# AST1060 register map
File version: 1.0
CPU: CM4 r0p1, little endian, MPU, FPU, 4 interrupt priority bits, 256 interrupts
Registers are 32-bit, read-write, reset 0x0 unless marked. A register's access mark holds for its fields unless they carry their own. Offsets are from the block's base; [hi:lo] are bit positions; {n}, {i} and the like mark numbered series.

## i2cbuff
Base 0x7E7B0C00
Same registers: i2cbuff{n} {0x7E7B0C00+0x20*n} (n=1..13)
{0x0+4i} BUFF[{i}] (i=0..7) — I2C Buffer Mode Buff
  [31:0] Data

## i2cfilter
Base 0x7E7B2000
0x08 I2CFILTER008 — I2CFLT\_IRQEN
  [15:0] TOPIRQEN
0x0C I2CFILTER00C — I2CFLT\_IRQSTA
  [15:0] TOPIRQSTA ro

## i2c_filter_thr
Base 0x7E7B2200
Same registers: i2c_filter_thr1 0x7E7B2300, i2c_filter_thr2 0x7E7B2400, i2c_filter_thr3 0x7E7B2500
0x04 I2CFILTERTHR04 — I2CFLT\_THRN\_EN
  [0] EN
0x08 I2CFILTERTHR08 — I2CFLT\_THRN\_ADR
  [31:0] ADDR
0x0C I2CFILTERTHR0C — I2CFLT\_THRN\_CFG
  [31:0] CFG
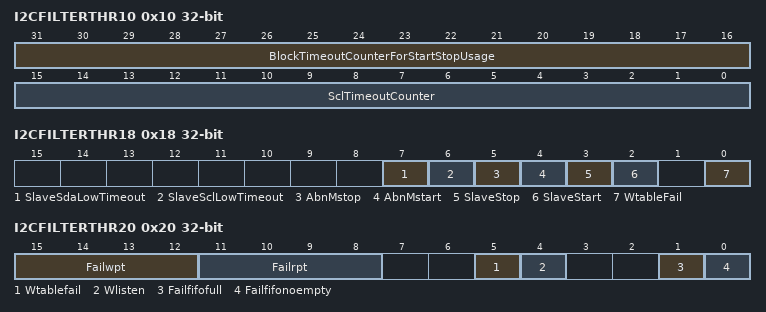
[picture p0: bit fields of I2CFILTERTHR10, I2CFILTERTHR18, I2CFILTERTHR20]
0x10 I2CFILTERTHR10 — I2CFLT\_THRN\_TMR
  [31:16] BlockTimeoutCounterForStartStopUsage, [15:0] SclTimeoutCounter
0x14 I2CFILTERTHR14 — I2CFLT\_THRN\_INTEN
  [7:0] INTEN
0x18 I2CFILTERTHR18 — I2CFLT\_THRN\_INTS
  [7] SlaveSdaLowTimeout
  [6] SlaveSclLowTimeout
  [5] AbnMstop — abnormal mstop
  [4] AbnMstart — abnormal mstart
  [3] SlaveStop
  [2] SlaveStart
  [0] WtableFail
0x20 I2CFILTERTHR20 — I2CFLT\_THRN\_STATUS
  [15:12] Failwpt, [11:8] Failrpt, [5] Wtablefail, [4] Wlisten, [1] Failfifofull, [0] Failfifonoempty
0x24 I2CFILTERTHR24 — I2CFLT\_THRN\_SEQ
  [31:0] RXSEQVAL ro
0x40 I2CFILTERTHR40 — I2CFLT\_THRN\_MAP0
  [31:0] MAP0
0x44 I2CFILTERTHR44 — I2CFLT\_THRN\_MAP1
  [31:0] MAP1
0x48 I2CFILTERTHR48 — I2CFLT\_THRN\_MAP2
  [31:0] MAP2
0x4C I2CFILTERTHR4C — I2CFLT\_THRN\_MAP3
  [31:0] MAP3
0x60 I2CFILTERTHR60 — I2CFLT\_THRN\_INFO
  [31:0] INFO ro

## spipf
Base 0x7E791000
Same registers: spipf1 0x7E792000, spipf2 0x7E793000, spipf3 0x7E794000
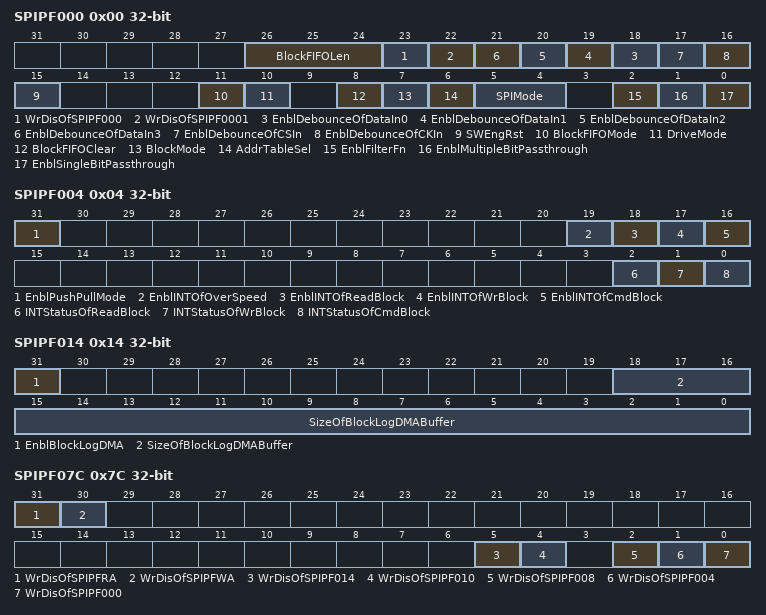
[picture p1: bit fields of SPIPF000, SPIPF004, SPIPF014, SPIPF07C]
0x00 SPIPF000 — Engine Control Register
  [26:24] BlockFIFOLen — Block FIFO length
  [23] WrDisOfSPIPF000 — Write Disable of hlinkSPIPF000
  [22] WrDisOfSPIPF0001 — Write Disable of hlinkSPIPF000
  [n+18] EnblDebounceOfDataIn{n} (n=0..3) — Enable Debounce of DataIn[{n}]
  [17] EnblDebounceOfCSIn — Enable Debounce of CSIn
  [16] EnblDebounceOfCKIn — Enable Debounce of CKIn
  [15] SWEngRst — SW Engine Reset
  [11] BlockFIFOMode
  [10] DriveMode
  [8] BlockFIFOClear
  [7] BlockMode
  [6] AddrTableSel — Address Table Selection
  [5:4] SPIMode
  [2] EnblFilterFn — Enable Filter function
  [1] EnblMultipleBitPassthrough — Enable Multiple Bit Passthrough
  [0] EnblSingleBitPassthrough — Enable Single Bit Passthrough
0x04 SPIPF004 — Interrupt Enable and Status Register
  [31] EnblPushPullMode — Enable push pull mode
  [19] EnblINTOfOverSpeed — Enable Interrupt of Over Speed
  [18] EnblINTOfReadBlock — Enable Interrupt of Read Block
  [17] EnblINTOfWrBlock — Enable Interrupt of Write Block
  [16] EnblINTOfCmdBlock — Enable Interrupt of Command Block
  [2] INTStatusOfReadBlock — Interrupt Status of Read Block
  [1] INTStatusOfWrBlock — Interrupt Status of Write Block
  [0] INTStatusOfCmdBlock — Interrupt Status of Command Block
0x08 SPIPF008 — EAR and Over Speed Register
  [7:0] CurExtendAddrRegRxdFromSPIMaster ro — Current Extend Address Register Received from SPI master
0x0C SPIPF00C — Block FIFO Data Register
  [31:0] ReadDataOfBlockFIFO ro
0x10 SPIPF010 — Block Log DMA Base Address
  [31:2] BlockLogDMABaseAddr
0x14 SPIPF014 — Block Log DMA Size
  [31] EnblBlockLogDMA — Enable Block Log DMA
  [18:0] SizeOfBlockLogDMABuffer
0x18 SPIPF018 — Block Log DMA Write Pointer
  [17:0] BlockLogDMAWrPointer ro
0x7C SPIPF07C — Write Disable Register
  [31] WrDisOfSPIPFRA — Write Disable of hlinkSPIPFRA
  [30] WrDisOfSPIPFWA — Write Disable of hlinkSPIPFWA
  [5] WrDisOfSPIPF014 — Write Disable of hlinkSPIPF014
  [4] WrDisOfSPIPF010 — Write Disable of hlinkSPIPF010
  [2] WrDisOfSPIPF008 — Write Disable of hlinkSPIPF008
  [1] WrDisOfSPIPF004 — Write Disable of hlinkSPIPF004
  [0] WrDisOfSPIPF000 — Write Disable of hlinkSPIPF000
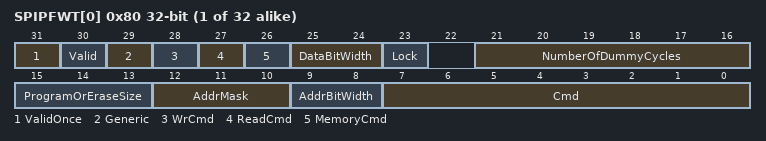
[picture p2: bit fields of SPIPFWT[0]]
{0x80+4i} SPIPFWT[{i}] (i=0..31) — Allow Command Table \#1 $\sim$ \#32
  [31] ValidOnce
  [30] Valid
  [29] Generic
  [28] WrCmd — Write Command
  [27] ReadCmd — Read Command
  [26] MemoryCmd — Memory Command
  [25:24] DataBitWidth
  [23] Lock
  [21:16] NumberOfDummyCycles
  [15:13] ProgramOrEraseSize
  [12:10] AddrMask — Address Mask
  [9:8] AddrBitWidth — Address Bit width
  [7:0] Cmd — Command
{0x100+4i} SPIPFWA[{i}] (i=0..511) — Write Address Table (\hlink{SPIPF000

## timer
Base 0x7E782000
Same registers: timer1 0x7E782010, timer2 0x7E782020, timer3 0x7E782040, timer4 0x7E782050, timer5 0x7E782060, timer6 0x7E782070, timer7 0x7E782080
0x00 TIMER000 — Counter \#1 Status Register
  [31:0] CounterSts — Counter status
0x04 TIMER004 — Counter \#1 Reload Value Register
  [31:0] CounterReloadValueReg — Counter reload value register
0x08 TIMER008 — Counter \#1 First Matching Register
  [31:0] FirstSetMatchReg — First set match register
0x0C TIMER00C — Counter \#1 Second Matching Register
  [31:0] SecondaryMatchReg — Secondary match register

## timerg
Base 0x7E782000
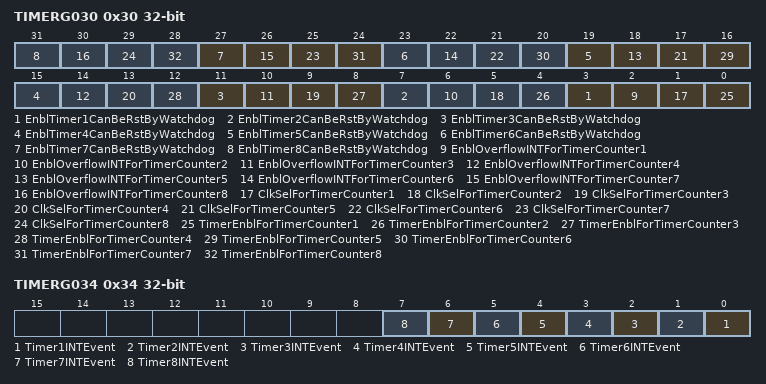
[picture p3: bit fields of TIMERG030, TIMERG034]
0x30 TIMERG030 — Control Register
  [4n-1] EnblTimer{n}CanBeRstByWatchdog (n=1..8) — Enable Timer #{n} can be reset by watchdog
  [4n-2] EnblOverflowINTForTimerCounter{n} (n=1..8) — Enable Overflow Interrupt for Timer/Counter #{n}
    0=Disable; 1=Enable_When_Timer_Overflow_Count_To_0_Occurred_Interrupt_Will_Be_Generated
  [4n-3] ClkSelForTimerCounter{n} (n=1..8) — Clock selection for Timer/Counter #{n}
    0=APB_Clock_PCLK; 1=1_MHz_Clock
  [4n-4] TimerEnblForTimerCounter{n} (n=1..8) — Timer enable for Timer/Counter #{n}
    0=Disable; 1=Enable
0x34 TIMERG034 — Interrupt Status Register
  [n-1] Timer{n}INTEvent (n=1..8) — Timer{n} Interrupt Event
0x3C TIMERG03C — TMC30 Clear Register
  [31:0] ClearTMC30
